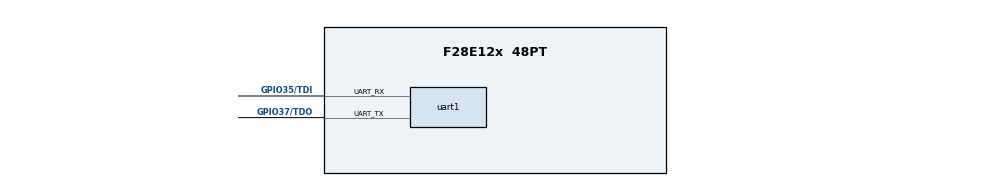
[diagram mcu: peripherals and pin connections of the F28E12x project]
/**
 * @cliArgs --device "F28E12x" --part "F28E12x_48PT" --package "48PT" --context "system"
 */
/**
 * Import the modules used in this configuration.
 */
const uart  = scripting.addModule("/driverlib/uart.js", {}, false);
const uart1 = uart.addInstance();
/**
 * Write custom configuration values to the imported modules.
 */
uart1.$name                    = "myUART0";
uart1.registerInterrupts       = true;
uart1.enabledInterrupts        = ["UART_INT_RX"];
uart1.fen                      = true;
uart1.txiflsel                 = "UART_FIFO_TX14";
uart1.rxiflsel                 = "UART_FIFO_RX2";
uart1.uart.$assign             = "UARTA";
uart1.uartInt.enableInterrupt  = true;
uart1.uartInt.interruptHandler = "UART_RX_IntHandler";
uart1.uart.uart_rxPin.$assign  = "GPIO35/TDI";
uart1.uart.uart_txPin.$assign  = "GPIO37/TDO";
